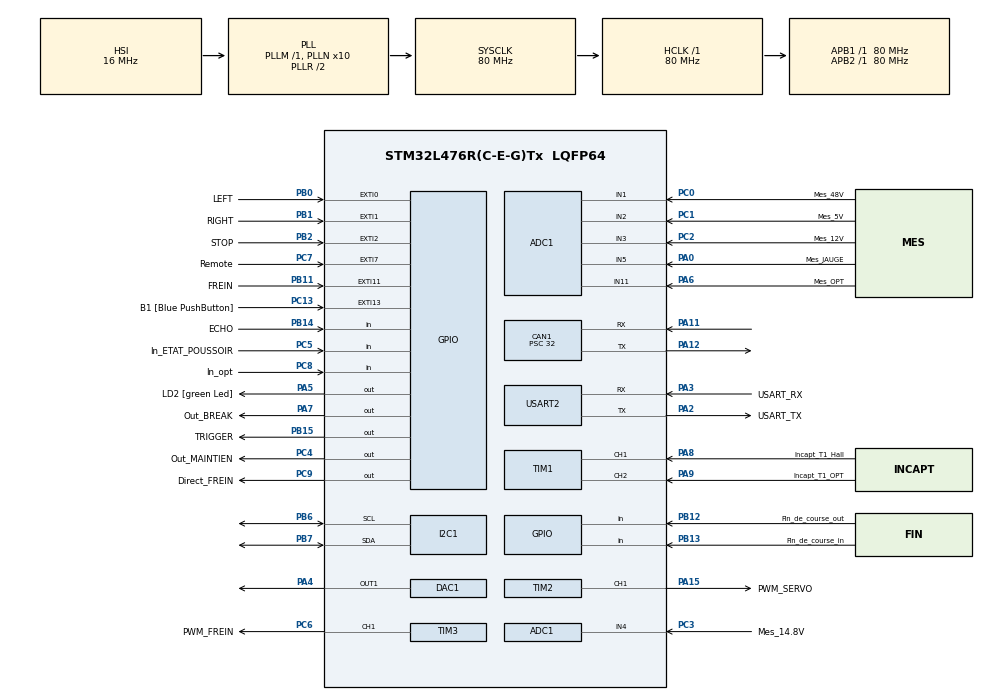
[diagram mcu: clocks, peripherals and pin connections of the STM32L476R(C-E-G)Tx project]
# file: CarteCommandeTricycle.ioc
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ADC1.Channel-0\#ChannelRegularConversion=ADC_CHANNEL_3
ADC1.NbrOfConversionFlag=1
ADC1.OffsetNumber-0\#ChannelRegularConversion=ADC_OFFSET_NONE
ADC1.Rank-0\#ChannelRegularConversion=1
ADC1.SamplingTime-0\#ChannelRegularConversion=ADC_SAMPLETIME_2CYCLES_5
ADC1.master=1
CAN1.BS1=CAN_BS1_2TQ
CAN1.BS2=CAN_BS2_2TQ
CAN1.CalculateBaudRate=500000
CAN1.CalculateTimeBit=2000
CAN1.CalculateTimeQuantum=400.0
CAN1.Prescaler=32
I2C1.Timing=0x10909CEC
Mcu.Family=STM32L4
Mcu.Name=STM32L476R(C-E-G)Tx
Mcu.Package=LQFP64
NVIC.CAN1_RX0_IRQn=true\:7\:0\:true\:false\:true\:true\:true
NVIC.EXTI0_IRQn=true\:4\:0\:true\:false\:true\:true\:true
NVIC.EXTI15_10_IRQn=true\:4\:0\:true\:false\:true\:true\:true
NVIC.EXTI1_IRQn=true\:4\:0\:true\:false\:true\:true\:true
NVIC.EXTI2_IRQn=true\:2\:0\:true\:false\:true\:true\:true
NVIC.EXTI9_5_IRQn=true\:4\:0\:true\:false\:true\:true\:true
NVIC.PriorityGroup=NVIC_PRIORITYGROUP_3
PA0.GPIO_Label=Mes_JAUGE
PA0.Signal=ADCx_IN5
PA11.GPIO_PuPd=GPIO_PULLUP
PA11.Mode=CAN_Activate
PA11.Signal=CAN1_RX
PA12.GPIO_PuPd=GPIO_PULLUP
PA12.Mode=CAN_Activate
PA12.Signal=CAN1_TX
PA13\ (JTMS-SWDIO).GPIO_Label=TMS
PA13\ (JTMS-SWDIO).Mode=Serial_Wire
PA13\ (JTMS-SWDIO).Signal=SYS_JTMS-SWDIO
PA14\ (JTCK-SWCLK).GPIO_Label=TCK
PA14\ (JTCK-SWCLK).Mode=Serial_Wire
PA14\ (JTCK-SWCLK).Signal=SYS_JTCK-SWCLK
PA15\ (JTDI).GPIO_Label=PWM_SERVO
PA15\ (JTDI).Signal=S_TIM2_CH1
PA2.GPIO_Label=USART_TX
PA2.GPIO_Mode=GPIO_MODE_AF_PP
PA2.GPIO_PuPd=GPIO_NOPULL
PA2.GPIO_Speed=GPIO_SPEED_FREQ_VERY_HIGH
PA2.Mode=Asynchronous
PA2.Signal=USART2_TX
PA3.GPIO_Label=USART_RX
PA3.GPIO_Mode=GPIO_MODE_AF_PP
PA3.GPIO_PuPd=GPIO_NOPULL
PA3.GPIO_Speed=GPIO_SPEED_FREQ_VERY_HIGH
PA3.Mode=Asynchronous
PA3.Signal=USART2_RX
PA4.GPIO_Mode=GPIO_MODE_ANALOG
PA4.GPIO_PuPd=GPIO_NOPULL
PA4.Signal=COMP_DAC11_group
PA5.GPIO_Label=LD2 [green Led]
PA5.GPIO_ModeDefaultOutputPP=GPIO_MODE_OUTPUT_PP
PA5.GPIO_PuPd=GPIO_NOPULL
PA5.GPIO_Speed=GPIO_SPEED_FREQ_LOW
PA5.Signal=GPIO_Output
PA6.GPIO_Label=Mes_OPT
PA6.Signal=ADCx_IN11
PA7.GPIO_Label=Out_BREAK
PA7.Signal=GPIO_Output
PA8.GPIO_Label=Incapt_T1_Hall
PA8.Signal=S_TIM1_CH1
PA9.GPIO_Label=Incapt_T1_OPT
PA9.Signal=S_TIM1_CH2
PB0.GPIO_Label=LEFT
PB0.GPIO_ModeDefaultEXTI=GPIO_MODE_IT_FALLING
PB0.GPIO_PuPd=GPIO_PULLUP
PB0.Signal=GPXTI0
PB1.GPIO_Label=RIGHT
PB1.GPIO_ModeDefaultEXTI=GPIO_MODE_IT_FALLING
PB1.GPIO_PuPd=GPIO_PULLUP
PB1.Signal=GPXTI1
PB11.GPIO_Label=FREIN
PB11.GPIO_ModeDefaultEXTI=GPIO_MODE_IT_RISING_FALLING
PB11.GPIO_PuPd=GPIO_PULLUP
PB11.Signal=GPXTI11
PB12.GPIO_Label=Fin_de_course_out
PB12.GPIO_PuPd=GPIO_PULLUP
PB12.Signal=GPIO_Input
PB13.GPIO_Label=Fin_de_course_in
PB13.GPIO_PuPd=GPIO_PULLUP
PB13.Signal=GPIO_Input
PB14.GPIO_Label=ECHO
PB14.Signal=GPIO_Input
PB15.GPIO_Label=TRIGGER
PB15.Signal=GPIO_Output
PB2.GPIO_Label=STOP
PB2.GPIO_ModeDefaultEXTI=GPIO_MODE_IT_FALLING
PB2.GPIO_PuPd=GPIO_PULLUP
PB2.Signal=GPXTI2
PB3\ (JTDO-TRACESWO).GPIO_Label=SWO
PB3\ (JTDO-TRACESWO).Signal=SYS_JTDO-SWO
PB6.GPIO_Pu=GPIO_PULLUP
PB6.Mode=I2C
PB6.Signal=I2C1_SCL
PB7.GPIO_Pu=GPIO_PULLUP
PB7.Mode=I2C
PB7.Signal=I2C1_SDA
PC0.GPIO_Label=Mes_48V
PC0.Signal=ADCx_IN1
PC1.GPIO_Label=Mes_5V
PC1.Signal=ADCx_IN2
PC13.GPIO_Label=B1 [Blue PushButton]
PC13.GPIO_ModeDefaultEXTI=GPIO_MODE_IT_FALLING
PC13.GPIO_PuPd=GPIO_NOPULL
PC13.Signal=GPXTI13
PC14-OSC32_IN\ (PC14).Mode=LSE-External-Oscillator
PC14-OSC32_IN\ (PC14).Signal=RCC_OSC32_IN
PC15-OSC32_OUT\ (PC15).Mode=LSE-External-Oscillator
PC15-OSC32_OUT\ (PC15).Signal=RCC_OSC32_OUT
PC2.GPIO_Label=Mes_12V
PC2.Signal=ADCx_IN3
PC3.GPIO_Label=Mes_14.8V
PC3.Signal=ADCx_IN4
PC4.GPIO_Label=Out_MAINTIEN
PC4.Signal=GPIO_Output
PC5.GPIO_Label=In_ETAT_POUSSOIR
PC5.Signal=GPIO_Input
PC6.GPIO_Label=PWM_FREIN
PC6.GPIO_ModeDefaultPP=GPIO_MODE_AF_PP
PC6.GPIO_PuPd=GPIO_NOPULL
PC6.GPIO_Speed=GPIO_SPEED_FREQ_LOW
PC6.Signal=S_TIM3_CH1
PC7.GPIO_Label=Remote
PC7.GPIO_ModeDefaultEXTI=GPIO_MODE_IT_RISING_FALLING
PC7.GPIO_PuPd=GPIO_PULLUP
PC7.Signal=GPXTI7
PC8.GPIO_Label=In_opt
PC8.Signal=GPIO_Input
PC9.GPIO_Label=Direct_FREIN
PC9.Signal=GPIO_Output
PH0-OSC_IN\ (PH0).Signal=RCC_OSC_IN
PH1-OSC_OUT\ (PH1).Signal=RCC_OSC_OUT
ProjectManager.HeapSize=0x200
ProjectManager.StackSize=0x400
ProjectManager.TargetToolchain=STM32CubeIDE
RCC.ADCFreq_Value=64000000
RCC.AHBFreq_Value=80000000
RCC.APB1Freq_Value=80000000
RCC.APB1TimFreq_Value=80000000
RCC.APB2Freq_Value=80000000
RCC.APB2TimFreq_Value=80000000
RCC.CortexFreq_Value=80000000
RCC.HCLKFreq_Value=80000000
RCC.HSE_VALUE=8000000
RCC.HSI_VALUE=16000000
RCC.MSI_VALUE=4000000
RCC.PLLN=10
RCC.PLLSourceVirtual=RCC_PLLSOURCE_HSI
RCC.PREFETCH_ENABLE=1
RCC.SYSCLKFreq_VALUE=80000000
RCC.SYSCLKSource=RCC_SYSCLKSOURCE_PLLCLK
RCC.USBFreq_Value=64000000
RCC.VCOOutputFreq_Value=160000000
SH.ADCx_IN1.0=ADC1_IN1,IN1-Single-Ended
SH.ADCx_IN11.0=ADC1_IN11,IN11-Single-Ended
SH.ADCx_IN2.0=ADC1_IN2,IN2-Single-Ended
SH.ADCx_IN3.0=ADC1_IN3,IN3-Single-Ended
SH.ADCx_IN4.0=ADC1_IN4,IN4-Single-Ended
SH.ADCx_IN5.0=ADC1_IN5,IN5-Single-Ended
SH.COMP_DAC11_group.0=DAC1_OUT1,DAC_OUT1
SH.S_TIM1_CH1.0=TIM1_CH1,Input_Capture1_from_TI1
SH.S_TIM1_CH2.0=TIM1_CH2,Input_Capture2_from_TI2
SH.S_TIM2_CH1.0=TIM2_CH1,PWM Generation1 CH1
SH.S_TIM3_CH1.0=TIM3_CH1,PWM Generation1 CH1
TIM1.Channel-Input_Capture1_from_TI1=TIM_CHANNEL_1
TIM1.Channel-Input_Capture2_from_TI2=TIM_CHANNEL_2
TIM2.Channel-PWM\ Generation1\ CH1=TIM_CHANNEL_1
TIM2.Period=20000
TIM2.Prescaler=80-1
TIM2.Pulse-PWM\ Generation1\ CH1=1500
TIM3.Channel-PWM\ Generation1\ CH1=TIM_CHANNEL_1
TIM3.Period=500
TIM3.Prescaler=8-1
TIM3.Pulse-PWM\ Generation1\ CH1=250
TIM4.Period=0
TIM4.Prescaler=80-1
USART2.VirtualMode-Asynchronous=VM_ASYNC
VP_TIM1_VS_ClockSourceINT.Mode=Internal
VP_TIM2_VS_ClockSourceINT.Mode=Internal
VP_TIM3_VS_ClockSourceINT.Mode=Internal
VP_TIM4_VS_ClockSourceINT.Mode=Internal
board=NUCLEO-L476RG

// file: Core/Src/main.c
/* USER CODE BEGIN Header */
/**
  ******************************************************************************
  * @file           : main.c
  * @brief          : Main program body
  ******************************************************************************
  * @attention
  *
  * <h2><center>&copy; Copyright (c) 2021 STMicroelectronics.
  * All rights reserved.</center></h2>
  *
  * This software component is licensed by ST under BSD 3-Clause license,
  * the "License"; You may not use this file except in compliance with the
  * License. You may obtain a copy of the License at:
  *                        opensource.org/licenses/BSD-3-Clause
  *
  ******************************************************************************
  */
/* USER CODE END Header */
#include <uart.h>
#include "main.h"

/* USER CODE BEGIN Includes */
#include "init.h"
/* USER CODE END Includes */

ADC_HandleTypeDef hadc1;

CAN_HandleTypeDef hcan1;

DAC_HandleTypeDef hdac1;

I2C_HandleTypeDef hi2c1;

TIM_HandleTypeDef htim1;
TIM_HandleTypeDef htim2;
TIM_HandleTypeDef htim3;
TIM_HandleTypeDef htim4;

UART_HandleTypeDef huart2;

void SystemClock_Config(void);
static void MX_GPIO_Init(void);
static void MX_USART2_UART_Init(void);
static void MX_ADC1_Init(void);
static void MX_DAC1_Init(void);
static void MX_I2C1_Init(void);
static void MX_TIM1_Init(void);
static void MX_TIM2_Init(void);
static void MX_TIM3_Init(void);
static void MX_CAN1_Init(void);
static void MX_TIM4_Init(void);

/* USER CODE BEGIN 0 */

/*
 uint8_t icFlag = 0;
uint8_t captureIdx=0;
uint32_t edge1Time=0, edge2Time=0;

const float speedOfSound = 0.0343/2;
 */

/* USER CODE END 0 */

int main(void)
{

  /* MCU Configuration--------------------------------------------------------*/

  /* Reset of all peripherals, Initializes the Flash interface and the Systick. */
  HAL_Init();

  /* Configure the system clock */
  SystemClock_Config();

  /* Initialize all configured peripherals */
  MX_GPIO_Init();
  MX_USART2_UART_Init();
  MX_ADC1_Init();
  MX_DAC1_Init();
  MX_I2C1_Init();
  MX_TIM1_Init();
  MX_TIM2_Init();
	MX_TIM3_Init();
	MX_CAN1_Init();
	MX_TIM4_Init();
  /* USER CODE BEGIN 2 */
	Main();
  /* USER CODE END 2 */

  /* Infinite loop */
  while (1)
  {

  }
}

void SystemClock_Config(void)
{
  RCC_OscInitTypeDef RCC_OscInitStruct = {0};
  RCC_ClkInitTypeDef RCC_ClkInitStruct = {0};

  /** Configure the main internal regulator output voltage
  */
  if (HAL_PWREx_ControlVoltageScaling(PWR_REGULATOR_VOLTAGE_SCALE1) != HAL_OK)
  {
	  Error_Handler();
  }
	/** Initializes the RCC Oscillators according to the specified parameters
	* in the RCC_OscInitTypeDef structure.
	*/
	RCC_OscInitStruct.OscillatorType = RCC_OSCILLATORTYPE_HSI;
	RCC_OscInitStruct.HSIState = RCC_HSI_ON;
	RCC_OscInitStruct.HSICalibrationValue = RCC_HSICALIBRATION_DEFAULT;
	RCC_OscInitStruct.PLL.PLLState = RCC_PLL_ON;
	RCC_OscInitStruct.PLL.PLLSource = RCC_PLLSOURCE_HSI;
	RCC_OscInitStruct.PLL.PLLM = 1;
	RCC_OscInitStruct.PLL.PLLN = 10;
	RCC_OscInitStruct.PLL.PLLP = RCC_PLLP_DIV7;
	RCC_OscInitStruct.PLL.PLLQ = RCC_PLLQ_DIV2;
	RCC_OscInitStruct.PLL.PLLR = RCC_PLLR_DIV2;
	if (HAL_RCC_OscConfig(&RCC_OscInitStruct) != HAL_OK) {
		Error_Handler();
	}
	/** Initializes the CPU, AHB and APB buses clocks
	*/
	RCC_ClkInitStruct.ClockType = RCC_CLOCKTYPE_HCLK | RCC_CLOCKTYPE_SYSCLK
	                              | RCC_CLOCKTYPE_PCLK1 | RCC_CLOCKTYPE_PCLK2;
	RCC_ClkInitStruct.SYSCLKSource = RCC_SYSCLKSOURCE_PLLCLK;
	RCC_ClkInitStruct.AHBCLKDivider = RCC_SYSCLK_DIV1;
	RCC_ClkInitStruct.APB1CLKDivider = RCC_HCLK_DIV1;
	RCC_ClkInitStruct.APB2CLKDivider = RCC_HCLK_DIV1;

	if (HAL_RCC_ClockConfig(&RCC_ClkInitStruct, FLASH_LATENCY_4) != HAL_OK) {
		Error_Handler();
	}
}

static void MX_ADC1_Init(void)
{

  ADC_MultiModeTypeDef multimode = {0};
  ADC_ChannelConfTypeDef sConfig = {0};

  /** Common config
  */
  hadc1.Instance = ADC1;
  hadc1.Init.ClockPrescaler = ADC_CLOCK_ASYNC_DIV1;
  hadc1.Init.Resolution = ADC_RESOLUTION_12B;
  hadc1.Init.DataAlign = ADC_DATAALIGN_RIGHT;
  hadc1.Init.ScanConvMode = ADC_SCAN_DISABLE;
  hadc1.Init.EOCSelection = ADC_EOC_SINGLE_CONV;
  hadc1.Init.LowPowerAutoWait = DISABLE;
  hadc1.Init.ContinuousConvMode = DISABLE;
  hadc1.Init.NbrOfConversion = 1;
  hadc1.Init.DiscontinuousConvMode = DISABLE;
  hadc1.Init.ExternalTrigConv = ADC_SOFTWARE_START;
  hadc1.Init.ExternalTrigConvEdge = ADC_EXTERNALTRIGCONVEDGE_NONE;
  hadc1.Init.DMAContinuousRequests = DISABLE;
  hadc1.Init.Overrun = ADC_OVR_DATA_PRESERVED;
  hadc1.Init.OversamplingMode = DISABLE;
  if (HAL_ADC_Init(&hadc1) != HAL_OK)
  {
    Error_Handler();
  }
  /** Configure the ADC multi-mode
  */
  multimode.Mode = ADC_MODE_INDEPENDENT;
  if (HAL_ADCEx_MultiModeConfigChannel(&hadc1, &multimode) != HAL_OK)
  {
    Error_Handler();
  }
  /** Configure Regular Channel
  */
  sConfig.Channel = ADC_CHANNEL_3;
  sConfig.Rank = ADC_REGULAR_RANK_1;
  sConfig.SamplingTime = ADC_SAMPLETIME_2CYCLES_5;
  sConfig.SingleDiff = ADC_SINGLE_ENDED;
  sConfig.OffsetNumber = ADC_OFFSET_NONE;
  sConfig.Offset = 0;
  if (HAL_ADC_ConfigChannel(&hadc1, &sConfig) != HAL_OK)
  {
    Error_Handler();
  }

}

static void MX_CAN1_Init(void) {

	hcan1.Instance = CAN1;
	hcan1.Init.Prescaler = 32;
	hcan1.Init.Mode = CAN_MODE_NORMAL;
	hcan1.Init.SyncJumpWidth = CAN_SJW_1TQ;
	hcan1.Init.TimeSeg1 = CAN_BS1_2TQ;
	hcan1.Init.TimeSeg2 = CAN_BS2_2TQ;
	hcan1.Init.TimeTriggeredMode = DISABLE;
	hcan1.Init.AutoBusOff = DISABLE;
	hcan1.Init.AutoWakeUp = DISABLE;
	hcan1.Init.AutoRetransmission = DISABLE;
	hcan1.Init.ReceiveFifoLocked = DISABLE;
	hcan1.Init.TransmitFifoPriority = DISABLE;
	if (HAL_CAN_Init(&hcan1) != HAL_OK) {
		Error_Handler();
	}

}

static void MX_DAC1_Init(void)
{

  DAC_ChannelConfTypeDef sConfig = {0};

  /** DAC Initialization
  */
  hdac1.Instance = DAC1;
  if (HAL_DAC_Init(&hdac1) != HAL_OK)
  {
    Error_Handler();
  }
  /** DAC channel OUT1 config
  */
  sConfig.DAC_SampleAndHold = DAC_SAMPLEANDHOLD_DISABLE;
  sConfig.DAC_Trigger = DAC_TRIGGER_NONE;
  sConfig.DAC_OutputBuffer = DAC_OUTPUTBUFFER_ENABLE;
  sConfig.DAC_ConnectOnChipPeripheral = DAC_CHIPCONNECT_DISABLE;
  sConfig.DAC_UserTrimming = DAC_TRIMMING_FACTORY;
  if (HAL_DAC_ConfigChannel(&hdac1, &sConfig, DAC_CHANNEL_1) != HAL_OK)
  {
    Error_Handler();
  }

}

static void MX_I2C1_Init(void) {

	hi2c1.Instance = I2C1;
	hi2c1.Init.Timing = 0x10909CEC;
	hi2c1.Init.OwnAddress1 = 0;
	hi2c1.Init.AddressingMode = I2C_ADDRESSINGMODE_7BIT;
	hi2c1.Init.DualAddressMode = I2C_DUALADDRESS_DISABLE;
	hi2c1.Init.OwnAddress2 = 0;
	hi2c1.Init.OwnAddress2Masks = I2C_OA2_NOMASK;
	hi2c1.Init.GeneralCallMode = I2C_GENERALCALL_DISABLE;
	hi2c1.Init.NoStretchMode = I2C_NOSTRETCH_DISABLE;
	if (HAL_I2C_Init(&hi2c1) != HAL_OK) {
		Error_Handler();
	}
  /** Configure Analogue filter
  */
  if (HAL_I2CEx_ConfigAnalogFilter(&hi2c1, I2C_ANALOGFILTER_ENABLE) != HAL_OK)
  {
    Error_Handler();
  }
  /** Configure Digital filter
  */
  if (HAL_I2CEx_ConfigDigitalFilter(&hi2c1, 0) != HAL_OK)
  {
    Error_Handler();
  }

}

static void MX_TIM1_Init(void)
{

  TIM_ClockConfigTypeDef sClockSourceConfig = {0};
  TIM_MasterConfigTypeDef sMasterConfig = {0};
  TIM_IC_InitTypeDef sConfigIC = {0};

  htim1.Instance = TIM1;
  htim1.Init.Prescaler = 0;
  htim1.Init.CounterMode = TIM_COUNTERMODE_UP;
  htim1.Init.Period = 65535;
  htim1.Init.ClockDivision = TIM_CLOCKDIVISION_DIV1;
  htim1.Init.RepetitionCounter = 0;
  htim1.Init.AutoReloadPreload = TIM_AUTORELOAD_PRELOAD_DISABLE;
  if (HAL_TIM_Base_Init(&htim1) != HAL_OK)
  {
    Error_Handler();
  }
  sClockSourceConfig.ClockSource = TIM_CLOCKSOURCE_INTERNAL;
  if (HAL_TIM_ConfigClockSource(&htim1, &sClockSourceConfig) != HAL_OK)
  {
    Error_Handler();
  }
  if (HAL_TIM_IC_Init(&htim1) != HAL_OK)
  {
    Error_Handler();
  }
  sMasterConfig.MasterOutputTrigger = TIM_TRGO_RESET;
  sMasterConfig.MasterOutputTrigger2 = TIM_TRGO2_RESET;
  sMasterConfig.MasterSlaveMode = TIM_MASTERSLAVEMODE_DISABLE;
  if (HAL_TIMEx_MasterConfigSynchronization(&htim1, &sMasterConfig) != HAL_OK)
  {
    Error_Handler();
  }
  sConfigIC.ICPolarity = TIM_INPUTCHANNELPOLARITY_RISING;
  sConfigIC.ICSelection = TIM_ICSELECTION_DIRECTTI;
  sConfigIC.ICPrescaler = TIM_ICPSC_DIV1;
  sConfigIC.ICFilter = 0;
  if (HAL_TIM_IC_ConfigChannel(&htim1, &sConfigIC, TIM_CHANNEL_1) != HAL_OK)
  {
    Error_Handler();
  }
  if (HAL_TIM_IC_ConfigChannel(&htim1, &sConfigIC, TIM_CHANNEL_2) != HAL_OK)
  {
    Error_Handler();
  }

}

static void MX_TIM2_Init(void)
{

  TIM_ClockConfigTypeDef sClockSourceConfig = {0};
  TIM_MasterConfigTypeDef sMasterConfig = {0};
  TIM_OC_InitTypeDef sConfigOC = {0};

  htim2.Instance = TIM2;
  htim2.Init.Prescaler = 80-1;
  htim2.Init.CounterMode = TIM_COUNTERMODE_UP;
  htim2.Init.Period = 20000;
  htim2.Init.ClockDivision = TIM_CLOCKDIVISION_DIV1;
  htim2.Init.AutoReloadPreload = TIM_AUTORELOAD_PRELOAD_DISABLE;
  if (HAL_TIM_Base_Init(&htim2) != HAL_OK)
  {
    Error_Handler();
  }
  sClockSourceConfig.ClockSource = TIM_CLOCKSOURCE_INTERNAL;
  if (HAL_TIM_ConfigClockSource(&htim2, &sClockSourceConfig) != HAL_OK)
  {
    Error_Handler();
  }
  if (HAL_TIM_PWM_Init(&htim2) != HAL_OK)
  {
    Error_Handler();
  }
  sMasterConfig.MasterOutputTrigger = TIM_TRGO_RESET;
  sMasterConfig.MasterSlaveMode = TIM_MASTERSLAVEMODE_DISABLE;
  if (HAL_TIMEx_MasterConfigSynchronization(&htim2, &sMasterConfig) != HAL_OK)
  {
    Error_Handler();
  }
  sConfigOC.OCMode = TIM_OCMODE_PWM1;
  sConfigOC.Pulse = 1500;
  sConfigOC.OCPolarity = TIM_OCPOLARITY_HIGH;
  sConfigOC.OCFastMode = TIM_OCFAST_DISABLE;
  if (HAL_TIM_PWM_ConfigChannel(&htim2, &sConfigOC, TIM_CHANNEL_1) != HAL_OK)
  {
    Error_Handler();
  }
  HAL_TIM_MspPostInit(&htim2);

}

static void MX_TIM3_Init(void)
{

  TIM_ClockConfigTypeDef sClockSourceConfig = {0};
  TIM_MasterConfigTypeDef sMasterConfig = {0};
  TIM_OC_InitTypeDef sConfigOC = {0};

  htim3.Instance = TIM3;
  htim3.Init.Prescaler = 8-1;
  htim3.Init.CounterMode = TIM_COUNTERMODE_UP;
  htim3.Init.Period = 500;
  htim3.Init.ClockDivision = TIM_CLOCKDIVISION_DIV1;
  htim3.Init.AutoReloadPreload = TIM_AUTORELOAD_PRELOAD_DISABLE;
  if (HAL_TIM_Base_Init(&htim3) != HAL_OK)
  {
    Error_Handler();
  }
  sClockSourceConfig.ClockSource = TIM_CLOCKSOURCE_INTERNAL;
  if (HAL_TIM_ConfigClockSource(&htim3, &sClockSourceConfig) != HAL_OK)
  {
    Error_Handler();
  }
  if (HAL_TIM_PWM_Init(&htim3) != HAL_OK)
  {
    Error_Handler();
  }
  sMasterConfig.MasterOutputTrigger = TIM_TRGO_RESET;
  sMasterConfig.MasterSlaveMode = TIM_MASTERSLAVEMODE_DISABLE;
  if (HAL_TIMEx_MasterConfigSynchronization(&htim3, &sMasterConfig) != HAL_OK)
  {
    Error_Handler();
  }
  sConfigOC.OCMode = TIM_OCMODE_PWM1;
  sConfigOC.Pulse = 250;
  sConfigOC.OCPolarity = TIM_OCPOLARITY_HIGH;
  sConfigOC.OCFastMode = TIM_OCFAST_DISABLE;
  if (HAL_TIM_PWM_ConfigChannel(&htim3, &sConfigOC, TIM_CHANNEL_1) != HAL_OK)
  {
    Error_Handler();
  }
  HAL_TIM_MspPostInit(&htim3);

}

static void MX_TIM4_Init(void)
{

  TIM_ClockConfigTypeDef sClockSourceConfig = {0};
  TIM_MasterConfigTypeDef sMasterConfig = {0};

  htim4.Instance = TIM4;
  htim4.Init.Prescaler = 80-1;
  htim4.Init.CounterMode = TIM_COUNTERMODE_UP;
  htim4.Init.Period = 0;
  htim4.Init.ClockDivision = TIM_CLOCKDIVISION_DIV1;
  htim4.Init.AutoReloadPreload = TIM_AUTORELOAD_PRELOAD_DISABLE;
  if (HAL_TIM_Base_Init(&htim4) != HAL_OK)
  {
    Error_Handler();
  }
  sClockSourceConfig.ClockSource = TIM_CLOCKSOURCE_INTERNAL;
  if (HAL_TIM_ConfigClockSource(&htim4, &sClockSourceConfig) != HAL_OK)
  {
    Error_Handler();
  }
  sMasterConfig.MasterOutputTrigger = TIM_TRGO_RESET;
  sMasterConfig.MasterSlaveMode = TIM_MASTERSLAVEMODE_DISABLE;
  if (HAL_TIMEx_MasterConfigSynchronization(&htim4, &sMasterConfig) != HAL_OK)
  {
    Error_Handler();
  }

}

static void MX_USART2_UART_Init(void)
{

  huart2.Instance = USART2;
  huart2.Init.BaudRate = 115200;
  huart2.Init.WordLength = UART_WORDLENGTH_8B;
  huart2.Init.StopBits = UART_STOPBITS_1;
  huart2.Init.Parity = UART_PARITY_NONE;
  huart2.Init.Mode = UART_MODE_TX_RX;
  huart2.Init.HwFlowCtl = UART_HWCONTROL_NONE;
  huart2.Init.OverSampling = UART_OVERSAMPLING_16;
  huart2.Init.OneBitSampling = UART_ONE_BIT_SAMPLE_DISABLE;
  huart2.AdvancedInit.AdvFeatureInit = UART_ADVFEATURE_NO_INIT;
  if (HAL_UART_Init(&huart2) != HAL_OK)
  {
    Error_Handler();
  }

}

static void MX_GPIO_Init(void)
{
  GPIO_InitTypeDef GPIO_InitStruct = {0};

  /* GPIO Ports Clock Enable */
  __HAL_RCC_GPIOC_CLK_ENABLE();
  __HAL_RCC_GPIOH_CLK_ENABLE();
  __HAL_RCC_GPIOA_CLK_ENABLE();
  __HAL_RCC_GPIOB_CLK_ENABLE();

  /*Configure GPIO pin Output Level */
  HAL_GPIO_WritePin(GPIOA, LD2_Pin|Out_BREAK_Pin, GPIO_PIN_RESET);

  /*Configure GPIO pin Output Level */
  HAL_GPIO_WritePin(GPIOC, Out_MAINTIEN_Pin|Direct_FREIN_Pin, GPIO_PIN_RESET);

  /*Configure GPIO pin Output Level */
  HAL_GPIO_WritePin(TRIGGER_GPIO_Port, TRIGGER_Pin, GPIO_PIN_RESET);

  /*Configure GPIO pin : B1_Pin */
  GPIO_InitStruct.Pin = B1_Pin;
  GPIO_InitStruct.Mode = GPIO_MODE_IT_FALLING;
  GPIO_InitStruct.Pull = GPIO_NOPULL;
  HAL_GPIO_Init(B1_GPIO_Port, &GPIO_InitStruct);

  /*Configure GPIO pins : LD2_Pin Out_BREAK_Pin */
  GPIO_InitStruct.Pin = LD2_Pin|Out_BREAK_Pin;
  GPIO_InitStruct.Mode = GPIO_MODE_OUTPUT_PP;
  GPIO_InitStruct.Pull = GPIO_NOPULL;
  GPIO_InitStruct.Speed = GPIO_SPEED_FREQ_LOW;
  HAL_GPIO_Init(GPIOA, &GPIO_InitStruct);

  /*Configure GPIO pins : Out_MAINTIEN_Pin Direct_FREIN_Pin */
  GPIO_InitStruct.Pin = Out_MAINTIEN_Pin|Direct_FREIN_Pin;
  GPIO_InitStruct.Mode = GPIO_MODE_OUTPUT_PP;
  GPIO_InitStruct.Pull = GPIO_NOPULL;
  GPIO_InitStruct.Speed = GPIO_SPEED_FREQ_LOW;
  HAL_GPIO_Init(GPIOC, &GPIO_InitStruct);

  /*Configure GPIO pins : In_ETAT_POUSSOIR_Pin In_opt_Pin */
  GPIO_InitStruct.Pin = In_ETAT_POUSSOIR_Pin|In_opt_Pin;
  GPIO_InitStruct.Mode = GPIO_MODE_INPUT;
  GPIO_InitStruct.Pull = GPIO_NOPULL;
  HAL_GPIO_Init(GPIOC, &GPIO_InitStruct);

  /*Configure GPIO pins : LEFT_Pin RIGHT_Pin STOP_Pin */
  GPIO_InitStruct.Pin = LEFT_Pin|RIGHT_Pin|STOP_Pin;
  GPIO_InitStruct.Mode = GPIO_MODE_IT_FALLING;
  GPIO_InitStruct.Pull = GPIO_PULLUP;
  HAL_GPIO_Init(GPIOB, &GPIO_InitStruct);

  /*Configure GPIO pin : FREIN_Pin */
  GPIO_InitStruct.Pin = FREIN_Pin;
  GPIO_InitStruct.Mode = GPIO_MODE_IT_RISING_FALLING;
  GPIO_InitStruct.Pull = GPIO_PULLUP;
  HAL_GPIO_Init(FREIN_GPIO_Port, &GPIO_InitStruct);

  /*Configure GPIO pins : Fin_de_course_out_Pin Fin_de_course_in_Pin */
  GPIO_InitStruct.Pin = Fin_de_course_out_Pin|Fin_de_course_in_Pin;
  GPIO_InitStruct.Mode = GPIO_MODE_INPUT;
  GPIO_InitStruct.Pull = GPIO_PULLUP;
  HAL_GPIO_Init(GPIOB, &GPIO_InitStruct);

  /*Configure GPIO pin : ECHO_Pin */
  GPIO_InitStruct.Pin = ECHO_Pin;
  GPIO_InitStruct.Mode = GPIO_MODE_INPUT;
  GPIO_InitStruct.Pull = GPIO_NOPULL;
  HAL_GPIO_Init(ECHO_GPIO_Port, &GPIO_InitStruct);

  /*Configure GPIO pin : TRIGGER_Pin */
  GPIO_InitStruct.Pin = TRIGGER_Pin;
  GPIO_InitStruct.Mode = GPIO_MODE_OUTPUT_PP;
  GPIO_InitStruct.Pull = GPIO_NOPULL;
  GPIO_InitStruct.Speed = GPIO_SPEED_FREQ_LOW;
  HAL_GPIO_Init(TRIGGER_GPIO_Port, &GPIO_InitStruct);

  /*Configure GPIO pin : Remote_Pin */
  GPIO_InitStruct.Pin = Remote_Pin;
  GPIO_InitStruct.Mode = GPIO_MODE_IT_RISING_FALLING;
  GPIO_InitStruct.Pull = GPIO_PULLUP;
  HAL_GPIO_Init(Remote_GPIO_Port, &GPIO_InitStruct);

  /* EXTI interrupt init*/
  HAL_NVIC_SetPriority(EXTI0_IRQn, 4, 0);
  HAL_NVIC_EnableIRQ(EXTI0_IRQn);

  HAL_NVIC_SetPriority(EXTI1_IRQn, 4, 0);
  HAL_NVIC_EnableIRQ(EXTI1_IRQn);

  HAL_NVIC_SetPriority(EXTI2_IRQn, 2, 0);
  HAL_NVIC_EnableIRQ(EXTI2_IRQn);

  HAL_NVIC_SetPriority(EXTI9_5_IRQn, 4, 0);
  HAL_NVIC_EnableIRQ(EXTI9_5_IRQn);

  HAL_NVIC_SetPriority(EXTI15_10_IRQn, 4, 0);
  HAL_NVIC_EnableIRQ(EXTI15_10_IRQn);

}

void Error_Handler(void)
{
  /* USER CODE BEGIN Error_Handler_Debug */
	uart_print("An unknown error happened..\r\n");
  /* USER CODE END Error_Handler_Debug */
}

/************************ (C) COPYRIGHT STMicroelectronics *****END OF FILE****/
